# ATtiny85 register map
Vendor: Atmel; File version: 1.0
CPU: other r0p0, little endian, no MPU, no FPU, 4 interrupt priority bits
Registers are 8-bit, read-write, reset 0x0 unless marked. A register's access mark holds for its fields unless they carry their own. Offsets are from the block's base; lines under a group give offsets from that group; [hi:lo] are bit positions; {n}, {i} and the like mark numbered series; 'fields as' and 'values as' point back to an identical list; <NAME> marks a mode.

## Memory map
0x00000000 FUSE size 0x3 — Fuses
0x00000000 LOCKBIT size 0x1 — Lockbits
0x00000023 AC blocks up to offset 0x12 — Analog Comparator
0x00000023 ADC blocks up to offset 0x12 — Analog-to-Digital Converter
0x0000002D USI size 0x4 — Universal Serial Interface
0x00000031 CPU blocks up to offset 0x25 — CPU Registers
0x00000035 EXINT blocks up to offset 0x27 — External Interrupts
0x00000036 PORTB size 0x3 — I/O Port
0x0000003C EEPROM size 0x4
0x00000041 WDT size 0x1 — Watchdog Timer
0x00000043 TC1 blocks up to offset 0x17 — Timer/Counter, 16-bit
0x00000048 TC0 blocks up to offset 0x12 — Timer/Counter, 8-bit
0x00000057 BOOT_LOAD size 0x1 — Bootloader

## Interrupts
0 RESET (CPU) — External Pin, Power-on Reset, Brown-out Reset,Watchdog Reset
1 INT0 (CPU) — External Interrupt 0
2 PCINT0 (CPU) — Pin change Interrupt Request 0
3 TIMER1_COMPA (CPU) — Timer/Counter1 Compare Match 1A
4 TIMER1_OVF (CPU) — Timer/Counter1 Overflow
5 TIMER0_OVF (CPU) — Timer/Counter0 Overflow
6 EE_RDY (CPU) — EEPROM Ready
7 ANA_COMP (CPU) — Analog comparator
8 ADC (CPU) — ADC Conversion ready
9 TIMER1_COMPB (CPU) — Timer/Counter1 Compare Match B
10 TIMER0_COMPA (CPU) — Timer/Counter0 Compare Match A
11 TIMER0_COMPB (CPU) — Timer/Counter0 Compare Match B
12 WDT (CPU) — Watchdog Time-out
13 USI_START (CPU)
14 USI_OVF (CPU) — USI Overflow

## AC — Analog Comparator
Base 0x00000023
0x00 ADCSRB — ADC Control and Status Register B
  [6] ACME — Analog Comparator Multiplexer Enable
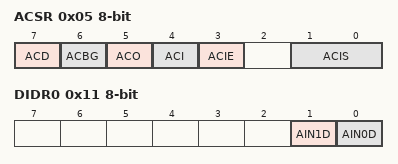
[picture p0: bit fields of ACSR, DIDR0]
0x05 ACSR — Analog Comparator Control And Status Register
  [7] ACD — Analog Comparator Disable
  [6] ACBG — Analog Comparator Bandgap Select
  [5] ACO — Analog Compare Output
  [4] ACI — Analog Comparator Interrupt Flag
  [3] ACIE — Analog Comparator Interrupt Enable
  [1:0] ACIS — Analog Comparator Interrupt Mode Select bits
    0=INTERRUPT_ON_TOGGLE; 2=INTERRUPT_ON_FALLING_EDGE; 3=INTERRUPT_ON_RISING_EDGE
0x11 DIDR0
  [1] AIN1D — AIN1 Digital Input Disable
  [0] AIN0D — AIN0 Digital Input Disable

## ADC — Analog-to-Digital Converter
Base 0x00000023
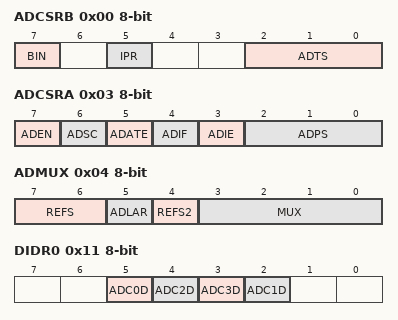
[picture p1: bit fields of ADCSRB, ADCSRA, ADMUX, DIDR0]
0x00 ADCSRB — ADC Control and Status Register B
  [7] BIN — Bipolar Input Mode
  [5] IPR — Input Polarity Mode
  [2:0] ADTS — ADC Auto Trigger Sources
    0=FREE_RUNNING_MODE; 1=ANALOG_COMPARATOR; 2=EXTERNAL_INTERRUPT_REQUEST_0; 3=TIMER_COUNTER0_COMPARE_MATCH_A; 4=TIMER_COUNTER0_OVERFLOW; 5=TIMER_COUNTER1_COMPARE_MATCH_B; 6=TIMER_COUNTER1_OVERFLOW; 7=TIMER_COUNTER1_CAPTURE_EVENT
0x01 ADC 16-bit (reset mask 0xFF) — ADC Data Register Bytes
0x03 ADCSRA — The ADC Control and Status register
  [7] ADEN — ADC Enable
  [6] ADSC — ADC Start Conversion
  [5] ADATE — ADC Auto Trigger Enable
  [4] ADIF — ADC Interrupt Flag
  [3] ADIE — ADC Interrupt Enable
  [2:0] ADPS — ADC Prescaler Select Bits
    1=2; 2=4; 3=8; 4=16; 5=32; 6=64; 7=128
0x04 ADMUX — The ADC multiplexer Selection Register
  [7:6] REFS — Reference Selection Bits
  [5] ADLAR — Left Adjust Result
  [4] REFS2 — Reference Selection Bit 2
  [3:0] MUX — Analog Channel and Gain Selection Bits
0x11 DIDR0 — Digital Input Disable Register 0
  [5] ADC0D — ADC0 Digital input Disable
  [4] ADC2D — ADC2 Digital input Disable
  [3] ADC3D — ADC3 Digital input Disable
  [2] ADC1D — ADC1 Digital input Disable

## BOOT_LOAD — Bootloader
Base 0x00000057
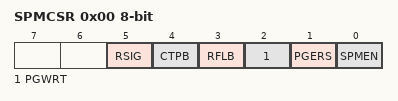
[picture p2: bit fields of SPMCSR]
0x00 SPMCSR — Store Program Memory Control Register
  [5] RSIG — Read Device Signature Imprint Table
  [4] CTPB — Clear temporary page buffer
  [3] RFLB — Read fuse and lock bits
  [2] PGWRT — Page Write
  [1] PGERS — Page Erase
  [0] SPMEN — Store Program Memory Enable
